# Z20K14xM register map
Vendor: Zhixin Semiconductor; Series: Z20K14xM; File version: 0.1.0
CPU: CM4 r0p1, little endian, no MPU, FPU, 4 interrupt priority bits
Registers are 32-bit, read-write, reset 0x0 unless marked. A register's access mark holds for its fields unless they carry their own. Offsets are from the block's base; [hi:lo] are bit positions; {n}, {i} and the like mark numbered series.

## TDG0
Base 0x4000F000
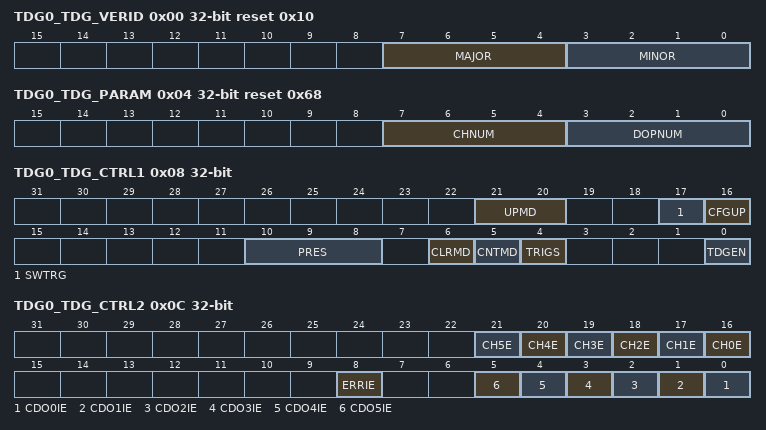
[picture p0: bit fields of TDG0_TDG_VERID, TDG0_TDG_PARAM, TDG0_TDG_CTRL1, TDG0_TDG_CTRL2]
0x00 TDG0_TDG_VERID ro reset 0x10 — TDG Version Idenfication(TDG_VERID)
  [7:4] MAJOR — Major version
  [3:0] MINOR — Minor version
0x04 TDG0_TDG_PARAM ro reset 0x68 — TDG Parameter(TDG_PARAM)
  [7:4] CHNUM — Channel number
  [3:0] DOPNUM — Delay output point number
0x08 TDG0_TDG_CTRL1 — TDG Control Registers 1(TDG_CTRL1)
  [21:20] UPMD — Channel configulation update mode
  [17] SWTRG — Software trig
  [16] CFGUP — Configuration update
  [10:8] PRES — Prescalar
  [6] CLRMD — Counter clear mode
  [5] CNTMD — Count mode
  [4] TRIGS — Trig source select
  [0] TDGEN — TDG enabled.
0x0C TDG0_TDG_CTRL2 — TDG Control Register 2(TDG_CTRL2)
  [n+16] CH{n}E (n=0..5) — Channel {n} enable
  [8] ERRIE — Error interrupt enable
  [n] CDO{n}IE (n=0..5) — Channel {n} complete delay output interrupt enable
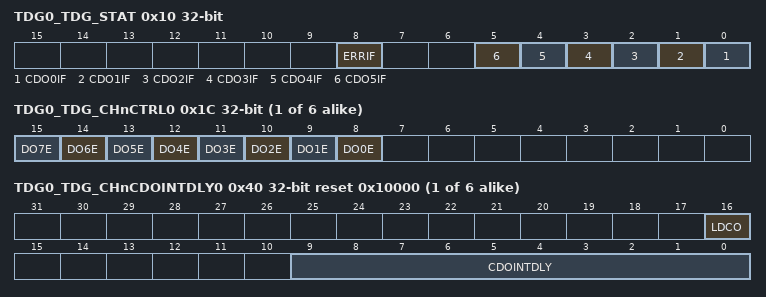
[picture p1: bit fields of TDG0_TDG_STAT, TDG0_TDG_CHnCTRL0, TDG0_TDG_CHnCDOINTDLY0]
0x10 TDG0_TDG_STAT — TDG Status Register(TDG_STAT)
  [8] ERRIF — Error interrupt flag
  [n] CDO{n}IF (n=0..5) — Channel {n} complete delay output interrupt flag
0x14 TDG0_TDG_MOD reset 0xFFFF — TDG Modulate Register(TDG_MOD)
  [15:0] MOD — TDG Modulate value.
0x18 TDG0_TDG_CNT ro — TDG Counter Register(TDG_CNT)
  [15:0] CNT — TDG counter value.
{0x1C+0x28*i} TDG0_TDG_CHnCTRL{i} (i=0..5) — TDG Channel n Control Register(TDG_CHnCTRL)
  [n+8] DO{n}E (n=0..7) — Delay output {n} enable on channel n
{0x20+4i} TDG0_TDG_CHnDO{i}OFS0 reset 0xFFFF (i=0..7) — TDG Channel n Delay Output {i} Offset Register(TDG_CHnDO{i}OFS)
  [15:0] DO{i}OFS — TDG Delay Output {i} Offset
{0x40+0x28*i} TDG0_TDG_CHnCDOINTDLY{i} reset 0x10000 (i=0..5) — TDG Channel n Complete Delay Output Interrupt Delay Register(TDG_CHnCDOINTDLY)
  [16] LDCO — CDO Interrupt Delay Configuration Load Complete
  [9:0] CDOINTDLY — TDG Complete Delay Output Interrupt Delay
{0x48+4i} TDG0_TDG_CHnDO{i}OFS1 reset 0xFFFF (i=0..7) — TDG Channel n Delay Output {i} Offset Register(TDG_CHnDO{i}OFS)
  [15:0] DO{i}OFS — TDG Delay Output {i} Offset
{0x70+4i} TDG0_TDG_CHnDO{i}OFS2 reset 0xFFFF (i=0..7) — TDG Channel n Delay Output {i} Offset Register(TDG_CHnDO{i}OFS)
  [15:0] DO{i}OFS — TDG Delay Output {i} Offset
{0x98+4i} TDG0_TDG_CHnDO{i}OFS3 reset 0xFFFF (i=0..7) — TDG Channel n Delay Output {i} Offset Register(TDG_CHnDO{i}OFS)
  [15:0] DO{i}OFS — TDG Delay Output {i} Offset
{0xC0+4i} TDG0_TDG_CHnDO{i}OFS4 reset 0xFFFF (i=0..7) — TDG Channel n Delay Output {i} Offset Register(TDG_CHnDO{i}OFS)
  [15:0] DO{i}OFS — TDG Delay Output {i} Offset
{0xE8+4i} TDG0_TDG_CHnDO{i}OFS5 reset 0xFFFF (i=0..7) — TDG Channel n Delay Output {i} Offset Register(TDG_CHnDO{i}OFS)
  [15:0] DO{i}OFS — TDG Delay Output {i} Offset

## TDG1
Base 0x4001B000
Registers as TDG0 (with TDG0 read as TDG1).

## FLASHC
Base 0x40020000
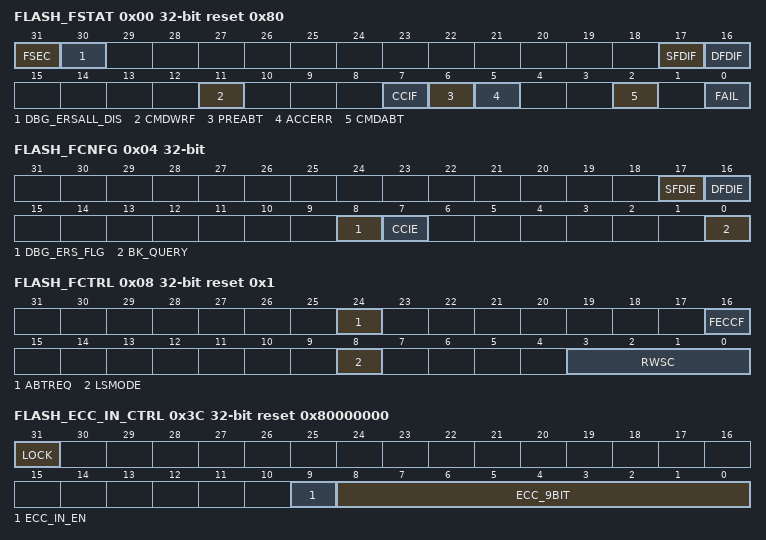
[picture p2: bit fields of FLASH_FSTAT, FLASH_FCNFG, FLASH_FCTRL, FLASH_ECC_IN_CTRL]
0x00 FLASH_FSTAT reset 0x80 — Flash Status Register
  [31] FSEC — Flash Security bit
  [30] DBG_ERSALL_DIS — debug erase all request disable
  [17] SFDIF — Single-bit Fault Detect Interrupt Flag
  [16] DFDIF — Double-bit Fault Detect Interrupt Flag
  [11] CMDWRF — Command writing flag
  [7] CCIF — Command Complete Interrupt Flag
  [6] PREABT — Pre-command Abort Flag
  [5] ACCERR — Command Access Error Flag
  [2] CMDABT — Command Abort Flag
  [0] FAIL — Command Fail Flag
0x04 FLASH_FCNFG — Flash Configuration Register
  [17] SFDIE — Single-bit Fault Detect Interrupt Enable
  [16] DFDIE — Double Bit Fault Detect Interrupt Enable
  [8] DBG_ERS_FLG — Debug Erase All Request
  [7] CCIE — Command Complete Interrupt Enable
  [0] BK_QUERY — Backdoor query
0x08 FLASH_FCTRL reset 0x1 — Flash Control Register
  [24] ABTREQ — Abort Request
  [16] FECCF — Force ECC Fault
  [8] LSMODE — Low speed active mode
  [3:0] RWSC — Read Wait-State Control
0x10 FLASH_FCMD — Flash Command Register
  [7:0] CMDCODE — Flash Command
0x14 FLASH_FCMD_OPT — Flash Command Option Register
  [7:0] CMDOPT — Flash option command
0x18 FLASH_FADDR — Flash Address Register
  [31:0] CMDADDR — flash sector/page/phrase address
0x1C FLASH_FADDR_END — Flash End Address Register
  [31:0] CMDADDRE — flash end address for page/phrase
{0x20+4i} FLASH_FDATA{i} (i=0..3) — Flash Data{i} Register
  [31:0] CMDDATA{i}
0x30 FLASH_BED_ADDR_STRT — Flash Bus Error Ignored Start Address Register
  [31:4] BED_ADDR_STRT — start address for bus error disable
0x34 FLASH_BED_ADDR_END reset 0xFFFFFFF0 — Flash Bus Error Ignored End Phrase Address Register
  [31:4] BED_ADDR_END — end address for bus error disable
0x38 FLASH_ECC_IN_ADDR — Flash ECC Injection Address Register
  [31:4] ECC_IN_ADDR — ECC injection address
0x3C FLASH_ECC_IN_CTRL reset 0x80000000 — Flash ECC Injection Control Register
  [31] LOCK — ECC register LOCK bit
  [9] ECC_IN_EN — ECC injection enable
  [8:0] ECC_9BIT — ECC injection on 9-bit ECC data
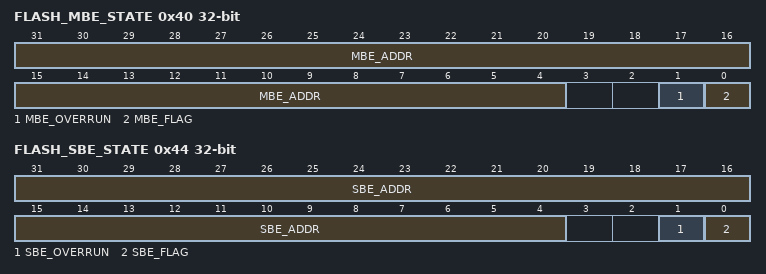
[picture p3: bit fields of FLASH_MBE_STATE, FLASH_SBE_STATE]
0x40 FLASH_MBE_STATE — Flash Multi-bit Error State Register
  [31:4] MBE_ADDR — multi-bit error address
  [1] MBE_OVERRUN — multi-bit error overrun
  [0] MBE_FLAG — multi-bit error flag
0x44 FLASH_SBE_STATE — Flash Single-bit Error State Register
  [31:4] SBE_ADDR — single-bit error address
  [1] SBE_OVERRUN — single-bit error overrun
  [0] SBE_FLAG — single-bit error flag
